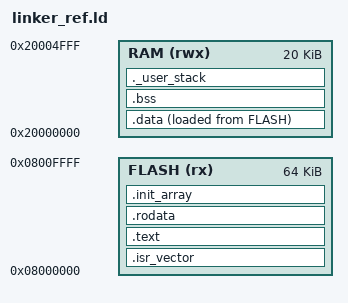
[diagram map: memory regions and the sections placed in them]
/*
 * =============================================================================
 * P2-M01 Challenge Reference Linker Script
 * STM32F103C8T6 (64 KB Flash, 20 KB RAM)
 * =============================================================================
 */

ENTRY(Reset_Handler)

MEMORY
{
    FLASH (rx)  : ORIGIN = 0x08000000, LENGTH = 64K
    RAM   (rwx) : ORIGIN = 0x20000000, LENGTH = 20K
}

_estack = ORIGIN(RAM) + LENGTH(RAM);
_min_stack_size = 0x400;

SECTIONS
{
    .isr_vector :
    {
        . = ALIGN(4);
        KEEP(*(.isr_vector))
        . = ALIGN(4);
    } > FLASH

    .text :
    {
        . = ALIGN(4);
        *(.text)
        *(.text*)
        . = ALIGN(4);
        _etext = .;
    } > FLASH

    .rodata :
    {
        . = ALIGN(4);
        *(.rodata)
        *(.rodata*)
        . = ALIGN(4);
    } > FLASH

    .init_array :
    {
        . = ALIGN(4);
        PROVIDE_HIDDEN (__init_array_start = .);
        KEEP (*(SORT(.init_array.*)))
        KEEP (*(.init_array*))
        PROVIDE_HIDDEN (__init_array_end = .);
        . = ALIGN(4);
    } > FLASH

    _sidata = LOADADDR(.data);

    .data :
    {
        . = ALIGN(4);
        _sdata = .;
        *(.data)
        *(.data*)
        . = ALIGN(4);
        _edata = .;
    } > RAM AT > FLASH

    .bss :
    {
        . = ALIGN(4);
        _sbss = .;
        *(.bss)
        *(.bss*)
        *(COMMON)
        . = ALIGN(4);
        _ebss = .;
    } > RAM

    ._user_stack :
    {
        . = ALIGN(8);
        . = . + _min_stack_size;
        . = ALIGN(8);
    } > RAM
}

ASSERT(_ebss + _min_stack_size <= ORIGIN(RAM) + LENGTH(RAM),
       "Linker Error: RAM exhausted!")

ASSERT(LOADADDR(.data) + SIZEOF(.data) <= ORIGIN(FLASH) + LENGTH(FLASH),
       "Linker Error: Flash exhausted!")
